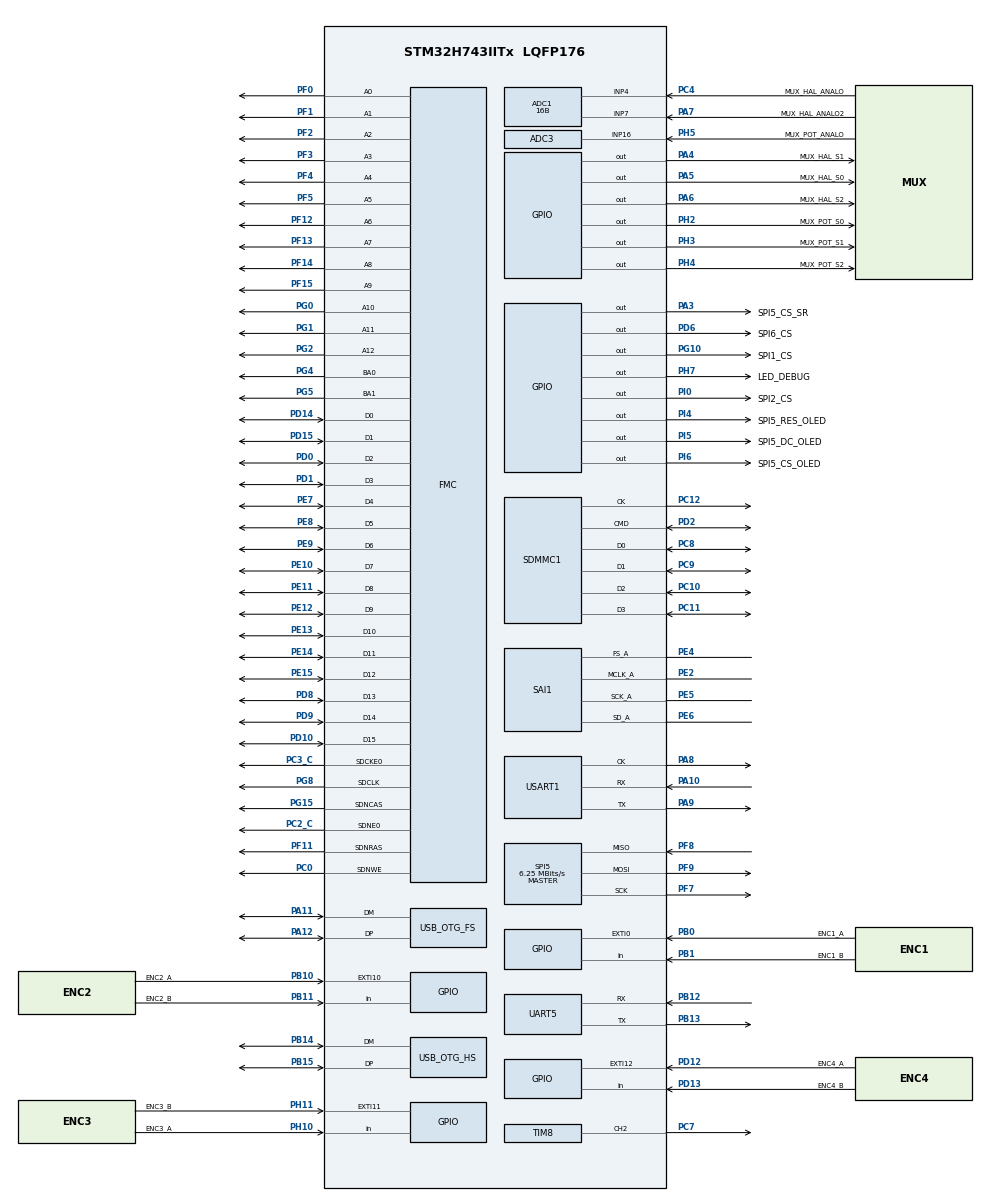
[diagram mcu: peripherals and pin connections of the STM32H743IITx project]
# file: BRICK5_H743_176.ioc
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ADC1.Channel-0\#ChannelRegularConversion=ADC_CHANNEL_7
ADC1.Channel-1\#ChannelRegularConversion=ADC_CHANNEL_7
ADC1.Channel-10\#ChannelRegularConversion=ADC_CHANNEL_4
ADC1.Channel-11\#ChannelRegularConversion=ADC_CHANNEL_4
ADC1.Channel-12\#ChannelRegularConversion=ADC_CHANNEL_4
ADC1.Channel-13\#ChannelRegularConversion=ADC_CHANNEL_4
ADC1.Channel-14\#ChannelRegularConversion=ADC_CHANNEL_4
ADC1.Channel-15\#ChannelRegularConversion=ADC_CHANNEL_4
ADC1.Channel-2\#ChannelRegularConversion=ADC_CHANNEL_7
ADC1.Channel-3\#ChannelRegularConversion=ADC_CHANNEL_7
ADC1.Channel-4\#ChannelRegularConversion=ADC_CHANNEL_7
ADC1.Channel-5\#ChannelRegularConversion=ADC_CHANNEL_7
ADC1.Channel-6\#ChannelRegularConversion=ADC_CHANNEL_7
ADC1.Channel-7\#ChannelRegularConversion=ADC_CHANNEL_7
ADC1.Channel-8\#ChannelRegularConversion=ADC_CHANNEL_4
ADC1.Channel-9\#ChannelRegularConversion=ADC_CHANNEL_4
ADC1.ClockPrescaler=ADC_CLOCK_ASYNC_DIV4
ADC1.ContinuousConvMode=DISABLE
ADC1.ConversionDataManagement=ADC_CONVERSIONDATA_DMA_CIRCULAR
ADC1.DiscontinuousConvMode=DISABLE
ADC1.EOCSelection=ADC_EOC_SEQ_CONV
ADC1.NbrOfConversion=16
ADC1.NbrOfConversionFlag=1
ADC1.OffsetNumber-0\#ChannelRegularConversion=ADC_OFFSET_NONE
ADC1.OffsetNumber-1\#ChannelRegularConversion=ADC_OFFSET_NONE
ADC1.OffsetNumber-10\#ChannelRegularConversion=ADC_OFFSET_NONE
ADC1.OffsetNumber-11\#ChannelRegularConversion=ADC_OFFSET_NONE
ADC1.OffsetNumber-12\#ChannelRegularConversion=ADC_OFFSET_NONE
ADC1.OffsetNumber-13\#ChannelRegularConversion=ADC_OFFSET_NONE
ADC1.OffsetNumber-14\#ChannelRegularConversion=ADC_OFFSET_NONE
ADC1.OffsetNumber-15\#ChannelRegularConversion=ADC_OFFSET_NONE
ADC1.OffsetNumber-2\#ChannelRegularConversion=ADC_OFFSET_NONE
ADC1.OffsetNumber-3\#ChannelRegularConversion=ADC_OFFSET_NONE
ADC1.OffsetNumber-4\#ChannelRegularConversion=ADC_OFFSET_NONE
ADC1.OffsetNumber-5\#ChannelRegularConversion=ADC_OFFSET_NONE
ADC1.OffsetNumber-6\#ChannelRegularConversion=ADC_OFFSET_NONE
ADC1.OffsetNumber-7\#ChannelRegularConversion=ADC_OFFSET_NONE
ADC1.OffsetNumber-8\#ChannelRegularConversion=ADC_OFFSET_NONE
ADC1.OffsetNumber-9\#ChannelRegularConversion=ADC_OFFSET_NONE
ADC1.OffsetSignedSaturation-0\#ChannelRegularConversion=DISABLE
ADC1.OffsetSignedSaturation-1\#ChannelRegularConversion=DISABLE
ADC1.OffsetSignedSaturation-10\#ChannelRegularConversion=DISABLE
ADC1.OffsetSignedSaturation-11\#ChannelRegularConversion=DISABLE
ADC1.OffsetSignedSaturation-12\#ChannelRegularConversion=DISABLE
ADC1.OffsetSignedSaturation-13\#ChannelRegularConversion=DISABLE
ADC1.OffsetSignedSaturation-14\#ChannelRegularConversion=DISABLE
ADC1.OffsetSignedSaturation-15\#ChannelRegularConversion=DISABLE
ADC1.OffsetSignedSaturation-2\#ChannelRegularConversion=DISABLE
ADC1.OffsetSignedSaturation-3\#ChannelRegularConversion=DISABLE
ADC1.OffsetSignedSaturation-4\#ChannelRegularConversion=DISABLE
ADC1.OffsetSignedSaturation-5\#ChannelRegularConversion=DISABLE
ADC1.OffsetSignedSaturation-6\#ChannelRegularConversion=DISABLE
ADC1.OffsetSignedSaturation-7\#ChannelRegularConversion=DISABLE
ADC1.OffsetSignedSaturation-8\#ChannelRegularConversion=DISABLE
ADC1.OffsetSignedSaturation-9\#ChannelRegularConversion=DISABLE
ADC1.Rank-0\#ChannelRegularConversion=1
ADC1.Rank-1\#ChannelRegularConversion=2
ADC1.Rank-10\#ChannelRegularConversion=11
ADC1.Rank-11\#ChannelRegularConversion=12
ADC1.Rank-12\#ChannelRegularConversion=13
ADC1.Rank-13\#ChannelRegularConversion=14
ADC1.Rank-14\#ChannelRegularConversion=15
ADC1.Rank-15\#ChannelRegularConversion=16
ADC1.Rank-2\#ChannelRegularConversion=3
ADC1.Rank-3\#ChannelRegularConversion=4
ADC1.Rank-4\#ChannelRegularConversion=5
ADC1.Rank-5\#ChannelRegularConversion=6
ADC1.Rank-6\#ChannelRegularConversion=7
ADC1.Rank-7\#ChannelRegularConversion=8
ADC1.Rank-8\#ChannelRegularConversion=9
ADC1.Rank-9\#ChannelRegularConversion=10
ADC1.Resolution=ADC_RESOLUTION_16B
ADC1.SamplingTime-0\#ChannelRegularConversion=ADC_SAMPLETIME_64CYCLES_5
ADC1.SamplingTime-1\#ChannelRegularConversion=ADC_SAMPLETIME_64CYCLES_5
ADC1.SamplingTime-10\#ChannelRegularConversion=ADC_SAMPLETIME_64CYCLES_5
ADC1.SamplingTime-11\#ChannelRegularConversion=ADC_SAMPLETIME_64CYCLES_5
ADC1.SamplingTime-12\#ChannelRegularConversion=ADC_SAMPLETIME_64CYCLES_5
ADC1.SamplingTime-13\#ChannelRegularConversion=ADC_SAMPLETIME_64CYCLES_5
ADC1.SamplingTime-14\#ChannelRegularConversion=ADC_SAMPLETIME_64CYCLES_5
ADC1.SamplingTime-15\#ChannelRegularConversion=ADC_SAMPLETIME_64CYCLES_5
ADC1.SamplingTime-2\#ChannelRegularConversion=ADC_SAMPLETIME_64CYCLES_5
ADC1.SamplingTime-3\#ChannelRegularConversion=ADC_SAMPLETIME_64CYCLES_5
ADC1.SamplingTime-4\#ChannelRegularConversion=ADC_SAMPLETIME_64CYCLES_5
ADC1.SamplingTime-5\#ChannelRegularConversion=ADC_SAMPLETIME_64CYCLES_5
ADC1.SamplingTime-6\#ChannelRegularConversion=ADC_SAMPLETIME_64CYCLES_5
ADC1.SamplingTime-7\#ChannelRegularConversion=ADC_SAMPLETIME_64CYCLES_5
ADC1.SamplingTime-8\#ChannelRegularConversion=ADC_SAMPLETIME_64CYCLES_5
ADC1.SamplingTime-9\#ChannelRegularConversion=ADC_SAMPLETIME_64CYCLES_5
ADC1.master=1
ADC3.Channel-1\#ChannelRegularConversion=ADC_CHANNEL_16
ADC3.Channel-2\#ChannelRegularConversion=ADC_CHANNEL_16
ADC3.Channel-3\#ChannelRegularConversion=ADC_CHANNEL_16
ADC3.Channel-4\#ChannelRegularConversion=ADC_CHANNEL_16
ADC3.Channel-5\#ChannelRegularConversion=ADC_CHANNEL_16
ADC3.Channel-6\#ChannelRegularConversion=ADC_CHANNEL_16
ADC3.Channel-7\#ChannelRegularConversion=ADC_CHANNEL_16
ADC3.Channel-8\#ChannelRegularConversion=ADC_CHANNEL_16
ADC3.ClockPrescaler=ADC_CLOCK_ASYNC_DIV4
ADC3.EnableRegularConversion=ENABLE
ADC3.NbrOfConversion=8
ADC3.NbrOfConversionFlag=1
ADC3.OffsetNumber-1\#ChannelRegularConversion=ADC_OFFSET_NONE
ADC3.OffsetNumber-2\#ChannelRegularConversion=ADC_OFFSET_NONE
ADC3.OffsetNumber-3\#ChannelRegularConversion=ADC_OFFSET_NONE
ADC3.OffsetNumber-4\#ChannelRegularConversion=ADC_OFFSET_NONE
ADC3.OffsetNumber-5\#ChannelRegularConversion=ADC_OFFSET_NONE
ADC3.OffsetNumber-6\#ChannelRegularConversion=ADC_OFFSET_NONE
ADC3.OffsetNumber-7\#ChannelRegularConversion=ADC_OFFSET_NONE
ADC3.OffsetNumber-8\#ChannelRegularConversion=ADC_OFFSET_NONE
ADC3.OffsetSignedSaturation-1\#ChannelRegularConversion=DISABLE
ADC3.OffsetSignedSaturation-2\#ChannelRegularConversion=DISABLE
ADC3.OffsetSignedSaturation-3\#ChannelRegularConversion=DISABLE
ADC3.OffsetSignedSaturation-4\#ChannelRegularConversion=DISABLE
ADC3.OffsetSignedSaturation-5\#ChannelRegularConversion=DISABLE
ADC3.OffsetSignedSaturation-6\#ChannelRegularConversion=DISABLE
ADC3.OffsetSignedSaturation-7\#ChannelRegularConversion=DISABLE
ADC3.OffsetSignedSaturation-8\#ChannelRegularConversion=DISABLE
ADC3.OversamplingMode=DISABLE
ADC3.Rank-1\#ChannelRegularConversion=1
ADC3.Rank-2\#ChannelRegularConversion=2
ADC3.Rank-3\#ChannelRegularConversion=3
ADC3.Rank-4\#ChannelRegularConversion=4
ADC3.Rank-5\#ChannelRegularConversion=5
ADC3.Rank-6\#ChannelRegularConversion=6
ADC3.Rank-7\#ChannelRegularConversion=7
ADC3.Rank-8\#ChannelRegularConversion=8
ADC3.SamplingTime-1\#ChannelRegularConversion=ADC_SAMPLETIME_387CYCLES_5
ADC3.SamplingTime-2\#ChannelRegularConversion=ADC_SAMPLETIME_387CYCLES_5
ADC3.SamplingTime-3\#ChannelRegularConversion=ADC_SAMPLETIME_387CYCLES_5
ADC3.SamplingTime-4\#ChannelRegularConversion=ADC_SAMPLETIME_387CYCLES_5
ADC3.SamplingTime-5\#ChannelRegularConversion=ADC_SAMPLETIME_387CYCLES_5
ADC3.SamplingTime-6\#ChannelRegularConversion=ADC_SAMPLETIME_387CYCLES_5
ADC3.SamplingTime-7\#ChannelRegularConversion=ADC_SAMPLETIME_387CYCLES_5
ADC3.SamplingTime-8\#ChannelRegularConversion=ADC_SAMPLETIME_387CYCLES_5
CORTEX_M7.default_mode_Activation=1
Dma.ADC1.1.Direction=DMA_PERIPH_TO_MEMORY
Dma.ADC1.1.EventEnable=DISABLE
Dma.ADC1.1.FIFOMode=DMA_FIFOMODE_DISABLE
Dma.ADC1.1.Instance=DMA1_Stream2
Dma.ADC1.1.MemDataAlignment=DMA_MDATAALIGN_HALFWORD
Dma.ADC1.1.MemInc=DMA_MINC_ENABLE
Dma.ADC1.1.Mode=DMA_CIRCULAR
Dma.ADC1.1.PeriphDataAlignment=DMA_PDATAALIGN_HALFWORD
Dma.ADC1.1.PeriphInc=DMA_PINC_DISABLE
Dma.ADC1.1.Polarity=HAL_DMAMUX_REQ_GEN_RISING
Dma.ADC1.1.Priority=DMA_PRIORITY_MEDIUM
Dma.ADC1.1.RequestNumber=1
Dma.ADC1.1.SignalID=NONE
Dma.ADC1.1.SyncEnable=DISABLE
Dma.ADC1.1.SyncPolarity=HAL_DMAMUX_SYNC_NO_EVENT
Dma.ADC1.1.SyncRequestNumber=1
Dma.ADC1.1.SyncSignalID=NONE
Dma.Request0=SAI1_A
Dma.Request1=ADC1
Dma.Request2=TIM8_CH2
Dma.SAI1_A.0.Direction=DMA_MEMORY_TO_PERIPH
Dma.SAI1_A.0.EventEnable=DISABLE
Dma.SAI1_A.0.FIFOMode=DMA_FIFOMODE_DISABLE
Dma.SAI1_A.0.Instance=DMA1_Stream0
Dma.SAI1_A.0.MemDataAlignment=DMA_MDATAALIGN_HALFWORD
Dma.SAI1_A.0.MemInc=DMA_MINC_ENABLE
Dma.SAI1_A.0.Mode=DMA_CIRCULAR
Dma.SAI1_A.0.PeriphDataAlignment=DMA_PDATAALIGN_HALFWORD
Dma.SAI1_A.0.PeriphInc=DMA_PINC_DISABLE
Dma.SAI1_A.0.Polarity=HAL_DMAMUX_REQ_GEN_RISING
Dma.SAI1_A.0.Priority=DMA_PRIORITY_VERY_HIGH
Dma.SAI1_A.0.RequestNumber=1
Dma.SAI1_A.0.SignalID=NONE
Dma.SAI1_A.0.SyncEnable=DISABLE
Dma.SAI1_A.0.SyncPolarity=HAL_DMAMUX_SYNC_NO_EVENT
Dma.SAI1_A.0.SyncRequestNumber=1
Dma.SAI1_A.0.SyncSignalID=NONE
Dma.TIM8_CH2.2.Direction=DMA_MEMORY_TO_PERIPH
Dma.TIM8_CH2.2.EventEnable=DISABLE
Dma.TIM8_CH2.2.FIFOMode=DMA_FIFOMODE_DISABLE
Dma.TIM8_CH2.2.Instance=DMA1_Stream3
Dma.TIM8_CH2.2.MemDataAlignment=DMA_MDATAALIGN_HALFWORD
Dma.TIM8_CH2.2.MemInc=DMA_MINC_ENABLE
Dma.TIM8_CH2.2.Mode=DMA_NORMAL
Dma.TIM8_CH2.2.PeriphDataAlignment=DMA_PDATAALIGN_HALFWORD
Dma.TIM8_CH2.2.PeriphInc=DMA_PINC_DISABLE
Dma.TIM8_CH2.2.Polarity=HAL_DMAMUX_REQ_GEN_RISING
Dma.TIM8_CH2.2.Priority=DMA_PRIORITY_MEDIUM
Dma.TIM8_CH2.2.RequestNumber=1
Dma.TIM8_CH2.2.SignalID=NONE
Dma.TIM8_CH2.2.SyncEnable=DISABLE
Dma.TIM8_CH2.2.SyncPolarity=HAL_DMAMUX_SYNC_NO_EVENT
Dma.TIM8_CH2.2.SyncRequestNumber=1
Dma.TIM8_CH2.2.SyncSignalID=NONE
FMC.CASLatency1=FMC_SDRAM_CAS_LATENCY_3
FMC.ColumnBitsNumber1=FMC_SDRAM_COLUMN_BITS_NUM_9
FMC.ExitSelfRefreshDelay1=8
FMC.LoadToActiveDelay1=2
FMC.RCDDelay1=2
FMC.RPDelay1=2
FMC.RPDelay2=2
FMC.RowCycleDelay1=6
FMC.RowCycleDelay2=6
FMC.SDClockPeriod1=FMC_SDRAM_CLOCK_PERIOD_2
FMC.SDClockPeriod2=FMC_SDRAM_CLOCK_PERIOD_2
FMC.SelfRefreshTime1=5
FMC.WriteRecoveryTime1=3
Mcu.Family=STM32H7
Mcu.Name=STM32H743IITx
Mcu.Package=LQFP176
NVIC.DMA1_Stream0_IRQn=true\:0\:0\:false\:false\:true\:false\:true\:true
NVIC.DMA1_Stream2_IRQn=true\:0\:0\:false\:false\:true\:false\:true\:true
NVIC.DMA1_Stream3_IRQn=true\:0\:0\:false\:false\:true\:false\:true\:true
NVIC.EXTI0_IRQn=true\:0\:0\:false\:false\:true\:true\:true\:true
NVIC.EXTI15_10_IRQn=true\:0\:0\:false\:false\:true\:true\:true\:true
NVIC.OTG_FS_IRQn=true\:0\:0\:false\:false\:true\:true\:true\:true
NVIC.OTG_HS_IRQn=true\:0\:0\:false\:false\:true\:true\:true\:true
NVIC.PriorityGroup=NVIC_PRIORITYGROUP_4
NVIC.SAI1_IRQn=true\:0\:0\:false\:false\:true\:true\:true\:true
PA10.Mode=Synchronous
PA10.Signal=USART1_RX
PA11.Mode=Device_Only
PA11.Signal=USB_OTG_FS_DM
PA12.Mode=Device_Only
PA12.Signal=USB_OTG_FS_DP
PA13\ (JTMS/SWDIO).Mode=Serial_Wire
PA13\ (JTMS/SWDIO).Signal=DEBUG_JTMS-SWDIO
PA14\ (JTCK/SWCLK).Mode=Serial_Wire
PA14\ (JTCK/SWCLK).Signal=DEBUG_JTCK-SWCLK
PA3.GPIO_Label=SPI5_CS_SR
PA3.PinState=GPIO_PIN_SET
PA3.Signal=GPIO_Output
PA4.GPIO_Label=MUX_HAL_S1
PA4.Signal=GPIO_Output
PA5.GPIO_Label=MUX_HAL_S0
PA5.Signal=GPIO_Output
PA6.GPIO_Label=MUX_HAL_S2
PA6.Signal=GPIO_Output
PA7.GPIO_Label=MUX_HAL_ANALO2
PA7.Signal=SharedAnalog_PA7
PA8.Mode=Synchronous
PA8.Signal=USART1_CK
PA9.Mode=Synchronous
PA9.Signal=USART1_TX
PB0.GPIO_Label=ENC1_A
PB0.GPIO_ModeDefaultEXTI=GPIO_MODE_IT_RISING_FALLING
PB0.GPIO_PuPd=GPIO_PULLUP
PB0.Signal=GPXTI0
PB1.GPIO_Label=ENC1_B
PB1.GPIO_PuPd=GPIO_PULLUP
PB1.Signal=GPIO_Input
PB10.GPIO_Label=ENC2_A
PB10.Signal=GPXTI10
PB11.GPIO_Label=ENC2_B
PB11.GPIO_PuPd=GPIO_PULLUP
PB11.Signal=GPIO_Input
PB12.Mode=Asynchronous
PB12.Signal=UART5_RX
PB13.Mode=Asynchronous
PB13.Signal=UART5_TX
PB14.Mode=Host_FS
PB14.Signal=USB_OTG_HS_DM
PB15.Mode=Host_FS
PB15.Signal=USB_OTG_HS_DP
PB3\ (JTDO/TRACESWO).Signal=SPI3_SCK
PB4\ (NJTRST).Signal=SPI3_MISO
PB5.Signal=SPI3_MOSI
PC0.Signal=FMC_SDNWE
PC10.Mode=SD_4_bits_Wide_bus
PC10.Signal=SDMMC1_D2
PC11.Mode=SD_4_bits_Wide_bus
PC11.Signal=SDMMC1_D3
PC12.Mode=SD_4_bits_Wide_bus
PC12.Signal=SDMMC1_CK
PC2_C.Mode=SdramChipSelect1_1
PC2_C.Signal=FMC_SDNE0
PC3_C.Mode=SdramChipSelect1_1
PC3_C.Signal=FMC_SDCKE0
PC4.GPIO_Label=MUX_HAL_ANALO
PC4.Signal=ADCx_INP4
PC7.GPIO_ModeDefaultPP=GPIO_MODE_AF_PP
PC7.GPIO_PuPd=GPIO_NOPULL
PC7.GPIO_Speed=GPIO_SPEED_FREQ_VERY_HIGH
PC7.Signal=S_TIM8_CH2
PC8.Mode=SD_4_bits_Wide_bus
PC8.Signal=SDMMC1_D0
PC9.Mode=SD_4_bits_Wide_bus
PC9.Signal=SDMMC1_D1
PD0.Signal=FMC_D2_DA2
PD1.Signal=FMC_D3_DA3
PD10.Signal=FMC_D15_DA15
PD12.GPIO_Label=ENC4_A
PD12.GPIO_ModeDefaultEXTI=GPIO_MODE_IT_RISING_FALLING
PD12.GPIO_PuPd=GPIO_PULLUP
PD12.Signal=GPXTI12
PD13.GPIO_Label=ENC4_B
PD13.GPIO_PuPd=GPIO_PULLUP
PD13.Signal=GPIO_Input
PD14.Signal=FMC_D0_DA0
PD15.Signal=FMC_D1_DA1
PD2.Mode=SD_4_bits_Wide_bus
PD2.Signal=SDMMC1_CMD
PD6.GPIO_Label=SPI6_CS
PD6.Signal=GPIO_Output
PD7.Signal=SPI1_MOSI
PD8.Signal=FMC_D13_DA13
PD9.Signal=FMC_D14_DA14
PE10.Signal=FMC_D7_DA7
PE11.Signal=FMC_D8_DA8
PE12.Signal=FMC_D9_DA9
PE13.Signal=FMC_D10_DA10
PE14.Signal=FMC_D11_DA11
PE15.Signal=FMC_D12_DA12
PE2.Mode=SAI_A_MasterWithClock
PE2.Signal=SAI1_MCLK_A
PE4.Mode=SAI_A_MasterWithClock
PE4.Signal=SAI1_FS_A
PE5.Mode=SAI_A_MasterWithClock
PE5.Signal=SAI1_SCK_A
PE6.Mode=SAI_A_MasterWithClock
PE6.Signal=SAI1_SD_A
PE7.Signal=FMC_D4_DA4
PE8.Signal=FMC_D5_DA5
PE9.Signal=FMC_D6_DA6
PF0.Signal=FMC_A0
PF1.Signal=FMC_A1
PF11.Signal=FMC_SDNRAS
PF12.Signal=FMC_A6
PF13.Signal=FMC_A7
PF14.Signal=FMC_A8
PF15.Signal=FMC_A9
PF2.Signal=FMC_A2
PF3.Signal=FMC_A3
PF4.Signal=FMC_A4
PF5.Signal=FMC_A5
PF7.GPIO_Speed=GPIO_SPEED_FREQ_VERY_HIGH
PF7.Mode=Full_Duplex_Master
PF7.Signal=SPI5_SCK
PF8.Mode=Full_Duplex_Master
PF8.Signal=SPI5_MISO
PF9.GPIO_PuPd=GPIO_NOPULL
PF9.GPIO_Speed=GPIO_SPEED_FREQ_VERY_HIGH
PF9.Mode=Full_Duplex_Master
PF9.Signal=SPI5_MOSI
PG0.Signal=FMC_A10
PG1.Signal=FMC_A11
PG10.GPIO_Label=SPI1_CS
PG10.Signal=GPIO_Output
PG11.Signal=SPI1_SCK
PG12.Signal=SPI6_MISO
PG13.Signal=SPI6_SCK
PG14.Signal=SPI6_MOSI
PG15.Signal=FMC_SDNCAS
PG2.Signal=FMC_A12
PG4.Signal=FMC_A14_BA0
PG5.Signal=FMC_A15_BA1
PG8.Signal=FMC_SDCLK
PG9.Signal=SPI1_MISO
PH0-OSC_IN\ (PH0).Mode=HSE-External-Oscillator
PH0-OSC_IN\ (PH0).Signal=RCC_OSC_IN
PH1-OSC_OUT\ (PH1).Mode=HSE-External-Oscillator
PH1-OSC_OUT\ (PH1).Signal=RCC_OSC_OUT
PH10.GPIO_Label=ENC3_A
PH10.GPIO_PuPd=GPIO_PULLUP
PH10.Signal=GPIO_Input
PH11.GPIO_Label=ENC3_B
PH11.GPIO_ModeDefaultEXTI=GPIO_MODE_IT_RISING_FALLING
PH11.GPIO_PuPd=GPIO_PULLUP
PH11.Signal=GPXTI11
PH2.GPIO_Label=MUX_POT_S0
PH2.Signal=GPIO_Output
PH3.GPIO_Label=MUX_POT_S1
PH3.Signal=GPIO_Output
PH4.GPIO_Label=MUX_POT_S2
PH4.Signal=GPIO_Output
PH5.GPIO_Label=MUX_POT_ANALO
PH5.Signal=SharedAnalog_PH5
PH7.GPIO_Label=LED_DEBUG
PH7.PinState=GPIO_PIN_SET
PH7.Signal=GPIO_Output
PI0.GPIO_Label=SPI2_CS
PI0.Signal=GPIO_Output
PI1.Signal=SPI2_SCK
PI4.GPIO_Label=SPI5_RES_OLED
PI4.PinState=GPIO_PIN_SET
PI4.Signal=GPIO_Output
PI5.GPIO_Label=SPI5_DC_OLED
PI5.PinState=GPIO_PIN_SET
PI5.Signal=GPIO_Output
PI6.GPIO_Label=SPI5_CS_OLED
PI6.PinAttribute=Free
PI6.PinState=GPIO_PIN_SET
PI6.Signal=GPIO_Output
ProjectManager.HeapSize=0x200
ProjectManager.StackSize=0x400
ProjectManager.TargetToolchain=STM32CubeIDE
RCC.ADCCLockSelection=RCC_ADCCLKSOURCE_PLL3
RCC.ADCFreq_Value=49151977.5390625
RCC.APB1Freq_Value=120000000
RCC.APB2Freq_Value=120000000
RCC.APB3Freq_Value=120000000
RCC.APB4Freq_Value=120000000
RCC.CortexFreq_Value=480000000
RCC.D1PPRE=RCC_APB3_DIV2
RCC.D2PPRE1=RCC_APB1_DIV2
RCC.D2PPRE2=RCC_APB2_DIV2
RCC.D3PPRE=RCC_APB4_DIV2
RCC.DIVM1=5
RCC.DIVM2=5
RCC.DIVM3=5
RCC.DIVN1=192
RCC.DIVN2=80
RCC.DIVN3=98
RCC.DIVP3=10
RCC.DIVQ1=4
RCC.DIVQ2=4
RCC.DIVQ3=10
RCC.DIVR2=4
RCC.DIVR3=10
RCC.FMCCLockSelection=RCC_FMCCLKSOURCE_PLL2
RCC.HCLKFreq_Value=240000000
RCC.HPRE=RCC_HCLK_DIV2
RCC.HSE_VALUE=25000000
RCC.PLL2FRACN=0
RCC.PLL3FRACN=2490
RCC.PLLFRACN=0
RCC.PLLSourceVirtual=RCC_PLLSOURCE_HSE
RCC.SAI1CLockSelection=RCC_SAI1CLKSOURCE_PLL3
RCC.SDMMC1CLockSelection=RCC_SDMMCCLKSOURCE_PLL2
RCC.SYSCLKFreq_VALUE=480000000
RCC.SYSCLKSource=RCC_SYSCLKSOURCE_PLLCLK
RCC.Spi45ClockSelection=RCC_SPI45CLKSOURCE_PLL2
RCC.USBCLockSelection=RCC_USBCLKSOURCE_HSI48
RCC.USBFreq_Value=48000000
SAI1.AudioFrequency-SAI_A_MasterWithClock=SAI_AUDIO_FREQUENCY_48K
SAI1.ErrorAudioFreq-SAI_A_MasterWithClock=299.99 %
SAI1.FIFOThreshold-SAI_A_MasterWithClock=SAI_FIFOTHRESHOLD_1QF
SAI1.InitProtocol-SAI_A_MasterWithClock=Enable
SAI1.Instance-SAI_A_MasterWithClock=SAI$Index_Block_A
SAI1.MClockEnable-SAI_A_MasterWithClock=SAI_MASTERCLOCK_ENABLE
SAI1.NoDivider-SAI_A_MasterWithClock=SAI_MCK_OVERSAMPLING_ENABLE
SAI1.RealAudioFreq-SAI_A_MasterWithClock=191.999 KHz
SAI1.VirtualMode-SAI_A_MasterWithClock=VM_MASTER
SAI1.VirtualProtocol-SAI_A_BASIC=VM_BASIC_PROTOCOL
SH.ADCx_INP4.0=ADC1_INP4,IN4-Single-Ended
SH.FMC_A0.0=FMC_A0,13b-sda1
SH.FMC_A1.0=FMC_A1,13b-sda1
SH.FMC_A10.0=FMC_A10,13b-sda1
SH.FMC_A11.0=FMC_A11,13b-sda1
SH.FMC_A12.0=FMC_A12,13b-sda1
SH.FMC_A14_BA0.0=FMC_BA0,FourSdramBanks1
SH.FMC_A15_BA1.0=FMC_BA1,FourSdramBanks1
SH.FMC_A2.0=FMC_A2,13b-sda1
SH.FMC_A3.0=FMC_A3,13b-sda1
SH.FMC_A4.0=FMC_A4,13b-sda1
SH.FMC_A5.0=FMC_A5,13b-sda1
SH.FMC_A6.0=FMC_A6,13b-sda1
SH.FMC_A7.0=FMC_A7,13b-sda1
SH.FMC_A8.0=FMC_A8,13b-sda1
SH.FMC_A9.0=FMC_A9,13b-sda1
SH.FMC_D0_DA0.0=FMC_D0,sd-16b-d1
SH.FMC_D10_DA10.0=FMC_D10,sd-16b-d1
SH.FMC_D11_DA11.0=FMC_D11,sd-16b-d1
SH.FMC_D12_DA12.0=FMC_D12,sd-16b-d1
SH.FMC_D13_DA13.0=FMC_D13,sd-16b-d1
SH.FMC_D14_DA14.0=FMC_D14,sd-16b-d1
SH.FMC_D15_DA15.0=FMC_D15,sd-16b-d1
SH.FMC_D1_DA1.0=FMC_D1,sd-16b-d1
SH.FMC_D2_DA2.0=FMC_D2,sd-16b-d1
SH.FMC_D3_DA3.0=FMC_D3,sd-16b-d1
SH.FMC_D4_DA4.0=FMC_D4,sd-16b-d1
SH.FMC_D5_DA5.0=FMC_D5,sd-16b-d1
SH.FMC_D6_DA6.0=FMC_D6,sd-16b-d1
SH.FMC_D7_DA7.0=FMC_D7,sd-16b-d1
SH.FMC_D8_DA8.0=FMC_D8,sd-16b-d1
SH.FMC_D9_DA9.0=FMC_D9,sd-16b-d1
SH.FMC_SDCLK.0=FMC_SDCLK,13b-sda1
SH.FMC_SDNCAS.0=FMC_SDNCAS,13b-sda1
SH.FMC_SDNRAS.0=FMC_SDNRAS,13b-sda1
SH.FMC_SDNWE.0=FMC_SDNWE,13b-sda1
SH.S_TIM8_CH2.0=TIM8_CH2,PWM Generation2 CH2
SH.SharedAnalog_PA7.0=ADC1_INN3
SH.SharedAnalog_PA7.1=ADC1_INP7,IN7-Single-Ended
SH.SharedAnalog_PH5.0=ADC3_INN15
SH.SharedAnalog_PH5.1=ADC3_INP16,IN16-Single-Ended
SPI5.BaudRatePrescaler=SPI_BAUDRATEPRESCALER_16
SPI5.CalculateBaudRate=6.25 MBits/s
SPI5.DataSize=SPI_DATASIZE_8BIT
SPI5.Direction=SPI_DIRECTION_2LINES
SPI5.Mode=SPI_MODE_MASTER
SPI5.VirtualType=VM_MASTER
TIM8.AutoReloadPreload=TIM_AUTORELOAD_PRELOAD_ENABLE
TIM8.Channel-PWM\ Generation2\ CH2=TIM_CHANNEL_2
TIM8.Period=249
USART1.VirtualMode-Synchronous=VM_SYNC
USB_OTG_FS.VirtualMode=Device_Only
USB_OTG_HS.VirtualMode-Host_FS=Host_FS
VP_MEMORYMAP_VS_MEMORYMAP.Mode=CurAppReg
VP_SAI1_VP_$IpInstance_SAIA_SAI_BASIC.Mode=SAI_A_BASIC
VP_SAI1_VP_$IpInstance_SYNCHRO_EXTERNAL.Mode=SynchroExternal
VP_TIM8_VS_ClockSourceINT.Mode=Internal
board=custom

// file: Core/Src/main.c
/* USER CODE BEGIN Header */
/**
  ******************************************************************************
  * @file           : main.c
  * @brief          : Main program body
  ******************************************************************************
  * @attention
  *
  * Copyright (c) 2025 STMicroelectronics.
  * All rights reserved.
  *
  * This software is licensed under terms that can be found in the LICENSE file
  * in the root directory of this software component.
  * If no LICENSE file comes with this software, it is provided AS-IS.
  *
  ******************************************************************************
  */
/* USER CODE END Header */
#include "main.h"
#include "adc.h"
#include "dma.h"
#include "sai.h"
#include "sdmmc.h"
#include "spi.h"
#include "tim.h"
#include "usart.h"
#include "usb_otg.h"
#include "gpio.h"
#include "fmc.h"

/* USER CODE BEGIN Includes */
#include "audio.h"

/* USER CODE END Includes */

void SystemClock_Config(void);
void PeriphCommonClock_Config(void);
static void MPU_Config(void);

int main(void)
{

  /* MPU Configuration--------------------------------------------------------*/
  MPU_Config();

  /* MCU Configuration--------------------------------------------------------*/

  /* Reset of all peripherals, Initializes the Flash interface and the Systick. */
  HAL_Init();

  /* Configure the system clock */
  SystemClock_Config();

  /* Configure the peripherals common clocks */
  PeriphCommonClock_Config();

  /* Initialize all configured peripherals */
  MX_GPIO_Init();
  MX_DMA_Init();
  MX_FMC_Init();
  MX_SAI1_Init();
  MX_SDMMC1_SD_Init();
  MX_UART5_Init();
  MX_USB_OTG_FS_PCD_Init();
  MX_USB_OTG_HS_HCD_Init();
  MX_SPI5_Init();
  MX_ADC1_Init();
  MX_ADC3_Init();
  MX_TIM8_Init();
  MX_USART1_Init();
  /* USER CODE BEGIN 2 */
  //audio_init();
  //audio_start();

  /* USER CODE END 2 */

  /* Infinite loop */
  while (1)
  {
	  HAL_GPIO_WritePin(LED_DEBUG_GPIO_Port, LED_DEBUG_Pin, GPIO_PIN_RESET); // LED ON
	  HAL_Delay(2000);

	  HAL_GPIO_WritePin(LED_DEBUG_GPIO_Port, LED_DEBUG_Pin, GPIO_PIN_SET);   // LED OFF
	  HAL_Delay(2000);
  }
}

void SystemClock_Config(void)
{
  RCC_OscInitTypeDef RCC_OscInitStruct = {0};
  RCC_ClkInitTypeDef RCC_ClkInitStruct = {0};

  /** Supply configuration update enable
  */
  HAL_PWREx_ConfigSupply(PWR_LDO_SUPPLY);

  /** Configure the main internal regulator output voltage
  */
  __HAL_PWR_VOLTAGESCALING_CONFIG(PWR_REGULATOR_VOLTAGE_SCALE0);

  while(!__HAL_PWR_GET_FLAG(PWR_FLAG_VOSRDY)) {}

  /** Initializes the RCC Oscillators according to the specified parameters
  * in the RCC_OscInitTypeDef structure.
  */
  RCC_OscInitStruct.OscillatorType = RCC_OSCILLATORTYPE_HSI48|RCC_OSCILLATORTYPE_HSE;
  RCC_OscInitStruct.HSEState = RCC_HSE_ON;
  RCC_OscInitStruct.HSI48State = RCC_HSI48_ON;
  RCC_OscInitStruct.PLL.PLLState = RCC_PLL_ON;
  RCC_OscInitStruct.PLL.PLLSource = RCC_PLLSOURCE_HSE;
  RCC_OscInitStruct.PLL.PLLM = 5;
  RCC_OscInitStruct.PLL.PLLN = 192;
  RCC_OscInitStruct.PLL.PLLP = 2;
  RCC_OscInitStruct.PLL.PLLQ = 4;
  RCC_OscInitStruct.PLL.PLLR = 2;
  RCC_OscInitStruct.PLL.PLLRGE = RCC_PLL1VCIRANGE_2;
  RCC_OscInitStruct.PLL.PLLVCOSEL = RCC_PLL1VCOWIDE;
  RCC_OscInitStruct.PLL.PLLFRACN = 0;
  if (HAL_RCC_OscConfig(&RCC_OscInitStruct) != HAL_OK)
  {
    Error_Handler();
  }

  /** Initializes the CPU, AHB and APB buses clocks
  */
  RCC_ClkInitStruct.ClockType = RCC_CLOCKTYPE_HCLK|RCC_CLOCKTYPE_SYSCLK
                              |RCC_CLOCKTYPE_PCLK1|RCC_CLOCKTYPE_PCLK2
                              |RCC_CLOCKTYPE_D3PCLK1|RCC_CLOCKTYPE_D1PCLK1;
  RCC_ClkInitStruct.SYSCLKSource = RCC_SYSCLKSOURCE_PLLCLK;
  RCC_ClkInitStruct.SYSCLKDivider = RCC_SYSCLK_DIV1;
  RCC_ClkInitStruct.AHBCLKDivider = RCC_HCLK_DIV2;
  RCC_ClkInitStruct.APB3CLKDivider = RCC_APB3_DIV2;
  RCC_ClkInitStruct.APB1CLKDivider = RCC_APB1_DIV2;
  RCC_ClkInitStruct.APB2CLKDivider = RCC_APB2_DIV2;
  RCC_ClkInitStruct.APB4CLKDivider = RCC_APB4_DIV2;

  if (HAL_RCC_ClockConfig(&RCC_ClkInitStruct, FLASH_LATENCY_4) != HAL_OK)
  {
    Error_Handler();
  }
}

void PeriphCommonClock_Config(void)
{
  RCC_PeriphCLKInitTypeDef PeriphClkInitStruct = {0};

  /** Initializes the peripherals clock
  */
  PeriphClkInitStruct.PeriphClockSelection = RCC_PERIPHCLK_FMC|RCC_PERIPHCLK_ADC
                              |RCC_PERIPHCLK_SDMMC|RCC_PERIPHCLK_SAI1
                              |RCC_PERIPHCLK_SPI5;
  PeriphClkInitStruct.PLL2.PLL2M = 5;
  PeriphClkInitStruct.PLL2.PLL2N = 80;
  PeriphClkInitStruct.PLL2.PLL2P = 2;
  PeriphClkInitStruct.PLL2.PLL2Q = 4;
  PeriphClkInitStruct.PLL2.PLL2R = 4;
  PeriphClkInitStruct.PLL2.PLL2RGE = RCC_PLL2VCIRANGE_2;
  PeriphClkInitStruct.PLL2.PLL2VCOSEL = RCC_PLL2VCOWIDE;
  PeriphClkInitStruct.PLL2.PLL2FRACN = 0;
  PeriphClkInitStruct.PLL3.PLL3M = 5;
  PeriphClkInitStruct.PLL3.PLL3N = 98;
  PeriphClkInitStruct.PLL3.PLL3P = 10;
  PeriphClkInitStruct.PLL3.PLL3Q = 10;
  PeriphClkInitStruct.PLL3.PLL3R = 10;
  PeriphClkInitStruct.PLL3.PLL3RGE = RCC_PLL3VCIRANGE_2;
  PeriphClkInitStruct.PLL3.PLL3VCOSEL = RCC_PLL3VCOWIDE;
  PeriphClkInitStruct.PLL3.PLL3FRACN = 2490;
  PeriphClkInitStruct.FmcClockSelection = RCC_FMCCLKSOURCE_PLL2;
  PeriphClkInitStruct.SdmmcClockSelection = RCC_SDMMCCLKSOURCE_PLL2;
  PeriphClkInitStruct.Sai1ClockSelection = RCC_SAI1CLKSOURCE_PLL3;
  PeriphClkInitStruct.Spi45ClockSelection = RCC_SPI45CLKSOURCE_PLL2;
  PeriphClkInitStruct.AdcClockSelection = RCC_ADCCLKSOURCE_PLL3;
  if (HAL_RCCEx_PeriphCLKConfig(&PeriphClkInitStruct) != HAL_OK)
  {
    Error_Handler();
  }
}

 /* MPU Configuration */

void MPU_Config(void)
{
  MPU_Region_InitTypeDef MPU_InitStruct = {0};

  /* Disables the MPU */
  HAL_MPU_Disable();

  /** Initializes and configures the Region and the memory to be protected
  */
  MPU_InitStruct.Enable = MPU_REGION_ENABLE;
  MPU_InitStruct.Number = MPU_REGION_NUMBER0;
  MPU_InitStruct.BaseAddress = 0x0;
  MPU_InitStruct.Size = MPU_REGION_SIZE_4GB;
  MPU_InitStruct.SubRegionDisable = 0x87;
  MPU_InitStruct.TypeExtField = MPU_TEX_LEVEL0;
  MPU_InitStruct.AccessPermission = MPU_REGION_NO_ACCESS;
  MPU_InitStruct.DisableExec = MPU_INSTRUCTION_ACCESS_DISABLE;
  MPU_InitStruct.IsShareable = MPU_ACCESS_SHAREABLE;
  MPU_InitStruct.IsCacheable = MPU_ACCESS_NOT_CACHEABLE;
  MPU_InitStruct.IsBufferable = MPU_ACCESS_NOT_BUFFERABLE;

  HAL_MPU_ConfigRegion(&MPU_InitStruct);
  /* Enables the MPU */
  HAL_MPU_Enable(MPU_PRIVILEGED_DEFAULT);

}

void Error_Handler(void)
{
  __disable_irq();
  while (1)
  {
  }
}
